# ExynosT100 register map
Vendor: SAMSUNG System LSI; Series: ARMCM4F; File version: 0.1
CPU: CM4 r1p0, little endian, MPU, FPU, 3 interrupt priority bits
Registers are 32-bit, read-write, reset 0x0 unless marked. A register's access mark holds for its fields unless they carry their own. Offsets are from the block's base; [hi:lo] are bit positions.

## NORREG — NOR Control
Base 0x40001000
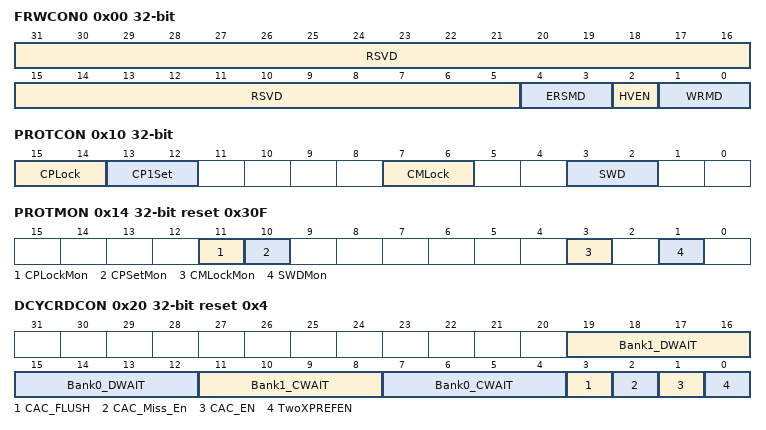
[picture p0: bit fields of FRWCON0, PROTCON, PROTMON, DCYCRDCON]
0x00 FRWCON0 (reset mask 0x1F) — Flash Memory Control Register
  [31:5] RSVD ro — Resered bits
  [4:3] ERSMD — Erase mode selection 00 = Page erase mode (256 bytes) 01 = Sector erase mode (4 Kbytes) 10 = Mat erase mode (Mat erase) 11 = Forbidden
  [2] HVEN — Program activation bit 0 = No operation 1 = High voltage generation
  [1:0] WRMD — Erase/write selection bits 00 = No operation 01 = Erase 10 = Write 11 = Forbidden
0x10 PROTCON wo — Code Protection Control Register
  [15:14] CPLock — 2'b10: can set CP (Code Protection) Set bit 2'b01: Locking CP Set bit (permanent lock) 1) Set these bits 2) Erase (OPT BASE+04) 3) Set these bits 4) Program (OPT BASE+04) NOTE: Since CP and CP lock shares the same page, two values should be updated together.[15:12]
  [13:12] CP1Set — 2'b10:CPA(Code Protection Area) is erasable 2'b01: CPA is read only 1) Set these bits 2) Erase (OPT BASE) 3) Set these bits 4) Program (OPT BASE) NOTE: Since CP and CP lock shares the same page, two values should be updated together.[15:12]
  [7:6] CMLock — 2'b10: can change SWD 2'b01: Locking change SWD (permanent lock) 1) Set these bits 2) Erase (OPT BASE+0x0C) 3) Set these bits 4) Program (OPT BASE+0x0C) NOTE: Since SWD, CM Lock, RSVD0, RSVD1 are written on the same page, they should be updated together.[7:0]
  [3:2] SWD — 2'b10: SWD(single wire debug) Enable 2'b01: SWD Disable 1) Set these bits 2) Erase (OPT BASE+04) 3) Set these bits 4) Program (OPT BASE+04) NOTE: Since SWD, CMLock , RSVD0, RSVD1 are written on the same page, they should be updated together.[7:0]
0x14 PROTMON ro reset 0x30F — Code Protection Status Register
  [11] CPLockMon — PROTCON CP Lock write enable bit 0 = PROTCON CP Lock is read only (irreversible setting) 1 = PROTCON CP Lock is writable
  [10] CPSetMon — CPA erase enable bit 0 = CPA is read only 1 = CPA is erasable
  [3] CMLockMon — 0 = You cannot change SWD option permanently 1 = You can change SWD option NOTE: 0 = user cannot change RSVD0 ~ CMLock Option in PROTCON(Lock)
  [1] SWDMon — 0 = SWD Disable 1 = SWD Enable
0x20 DCYCRDCON reset 0x4 — Double Cycle Read Control Register
  [19:16] Bank1_DWAIT — NOR flash bank1 data read wait cycle 0000 ~ 1111: 0~15 wait others: Forbidden NOTE 1) Cache mode supports only more than 2 wait. (Even if code wait is set to 0 or 1 wait, flash access cycle time always takes 3 cycles for cache miss.)
  [15:12] Bank0_DWAIT — NOR flash bank0 data read wait cycle 0000 ~ 1111: 0 ~ 15 wait others: Forbidden NOTE 1) Cache mode supports only more than 2 wait. (Even if code wait is set to 0 or 1 wait, Flash access cycle time always takes 3 cycles for cache miss.)
  [11:8] Bank1_CWAIT — NOR flash bank1 code read wait cycle 0000 ~ 1111: 0~15 wait others: Forbidden NOTE 1) Cache mode supports only more than 2 wait. (Even if code wait is set to 0 or 1 wait, flash access cycle time always takes 3 cycles for cache miss.) 2) Cache off mode support only 0 ~ 1 wait operation
  [7:4] Bank0_CWAIT — NOR flash bank0 code read wait cycle 0000 ~ 1111: 0 ~ 15 wait others: Forbidden NOTE 1) Cache mode supports only more than 2 wait. (Even if code wait is set to 0 or 1 wait, flash access cycle time always takes 3 cycles for cache miss.) 2) Cache off mode support only 0~1 wait operation.
  [3] CAC_FLUSH — NOR flash cache flush bit 0 = Remain cache 1 = Cache flush
  [2] CAC_Miss_En — NOR flash cache miss enable bit 0 = Cache miss disable 1 = Cache miss enable
  [1] CAC_EN — NOR flash cache enable bit 0 = Cache disable 1 = Cache enable
  [0] TwoXPREFEN — NOR flash 2X Prefetch control bit 0 = Prefetch disable 1 = Prefetch enable
